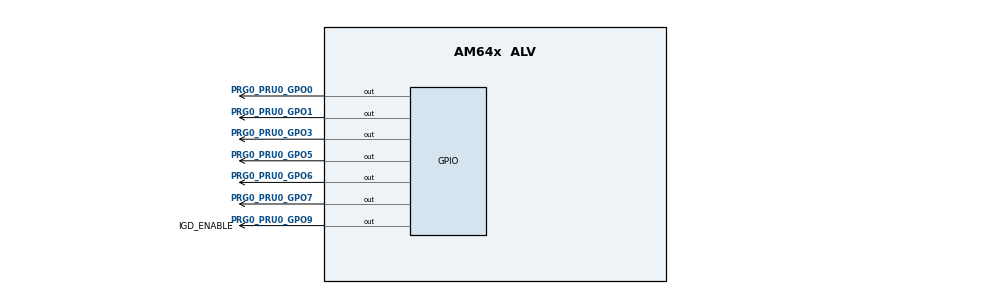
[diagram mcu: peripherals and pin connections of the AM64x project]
/**
 * @cliArgs --device "AM64x" --part "Default" --package "ALV" --context "r5fss0-0" --product "MCU_PLUS_SDK_AM64x@09.02.01"
 * @versions {"tool":"1.21.0+3721"}
 */

/**
 * Import the modules used in this configuration.
 */
const epwm       = scripting.addModule("/drivers/epwm/epwm", {}, false);
const epwm1      = epwm.addInstance();
const epwm2      = epwm.addInstance();
const epwm3      = epwm.addInstance();
const epwm4      = epwm.addInstance();
const gpio       = scripting.addModule("/drivers/gpio/gpio", {}, false);
const gpio1      = gpio.addInstance();
const gpio2      = gpio.addInstance();
const gpio3      = gpio.addInstance();
const gpio4      = gpio.addInstance();
const gpio5      = gpio.addInstance();
const gpio6      = gpio.addInstance();
const gpio7      = gpio.addInstance();
const i2c        = scripting.addModule("/drivers/i2c/i2c", {}, false);
const i2c1       = i2c.addInstance();
const mcspi      = scripting.addModule("/drivers/mcspi/mcspi", {}, false);
const mcspi1     = mcspi.addInstance();
const pruicss    = scripting.addModule("/drivers/pruicss/pruicss", {}, false);
const pruicss1   = pruicss.addInstance();
const udma       = scripting.addModule("/drivers/udma/udma", {}, false);
const udma1      = udma.addInstance();
const clock      = scripting.addModule("/kernel/dpl/clock");
const debug_log  = scripting.addModule("/kernel/dpl/debug_log");
const mpu_armv7  = scripting.addModule("/kernel/dpl/mpu_armv7", {}, false);
const mpu_armv71 = mpu_armv7.addInstance();
const mpu_armv72 = mpu_armv7.addInstance();
const mpu_armv73 = mpu_armv7.addInstance();
const mpu_armv74 = mpu_armv7.addInstance();
const mpu_armv75 = mpu_armv7.addInstance();
const mpu_armv76 = mpu_armv7.addInstance();
const pru_ipc    = scripting.addModule("/pru_io/pru_ipc/pru_ipc", {}, false);
const pru_ipc1   = pru_ipc.addInstance();

/**
 * Write custom configuration values to the imported modules.
 */
epwm1.$name            = "CONFIG_EPWM1";
epwm1.EPWM.$assign     = "EHRPWM4";
epwm1.EPWM.SYNCO.$used = false;
epwm1.EPWM.SYNCI.$used = false;

epwm2.$name            = "CONFIG_EPWM2";
epwm2.EPWM.$assign     = "EHRPWM5";
epwm2.EPWM.SYNCO.$used = false;
epwm2.EPWM.SYNCI.$used = false;

epwm3.$name            = "CONFIG_EPWM3";
epwm3.EPWM.$assign     = "EHRPWM6";
epwm3.EPWM.A.$assign   = "SPI1_CS0";
epwm3.EPWM.B.$assign   = "SPI1_D1";
epwm3.EPWM.SYNCO.$used = false;
epwm3.EPWM.SYNCI.$used = false;

epwm4.$name            = "CONFIG_EPWM0";
epwm4.EPWM.$assign     = "EHRPWM3";
epwm4.EPWM.A.$used     = false;
epwm4.EPWM.B.$used     = false;
epwm4.EPWM.SYNCO.$used = false;
epwm4.EPWM.SYNCI.$used = false;

gpio1.$name                = "CONFIG_GPIO0";
gpio1.pinDir               = "OUTPUT";
gpio1.trigType             = "BOTH_EDGE";
gpio1.GPIO.gpioPin.rx      = false;
gpio1.GPIO.gpioPin.$assign = "PRG0_PRU0_GPO0";

gpio2.$name                = "CONFIG_GPIO1";
gpio2.trigType             = "BOTH_EDGE";
gpio2.pinDir               = "OUTPUT";
gpio2.GPIO.gpioPin.rx      = false;
gpio2.GPIO.gpioPin.$assign = "PRG0_PRU0_GPO1";

gpio3.$name                = "CONFIG_GPIO2";
gpio3.trigType             = "BOTH_EDGE";
gpio3.pinDir               = "OUTPUT";
gpio3.GPIO.gpioPin.rx      = false;
gpio3.GPIO.gpioPin.$assign = "PRG0_PRU0_GPO3";

gpio4.$name                = "CONFIG_GPIO3";
gpio4.pinDir               = "OUTPUT";
gpio4.trigType             = "BOTH_EDGE";
gpio4.GPIO.gpioPin.rx      = false;
gpio4.GPIO.gpioPin.$assign = "PRG0_PRU0_GPO5";

gpio5.$name                = "CONFIG_GPIO4";
gpio5.pinDir               = "OUTPUT";
gpio5.trigType             = "BOTH_EDGE";
gpio5.GPIO.gpioPin.rx      = false;
gpio5.GPIO.gpioPin.$assign = "PRG0_PRU0_GPO6";

gpio6.$name                = "CONFIG_GPIO5";
gpio6.pinDir               = "OUTPUT";
gpio6.trigType             = "BOTH_EDGE";
gpio6.GPIO.$assign         = "GPIO1";
gpio6.GPIO.gpioPin.rx      = false;
gpio6.GPIO.gpioPin.$assign = "PRG0_PRU0_GPO7";

gpio7.pinDir               = "OUTPUT";
gpio7.$name                = "IGD_ENABLE";
gpio7.GPIO.gpioPin.rx      = false;
gpio7.GPIO.gpioPin.$assign = "PRG0_PRU0_GPO9";

i2c1.$name               = "CONFIG_I2C0";
i2c1.transferMode        = "CALLBACK";
i2c1.transferCallbackFxn = "i2cCallback";
i2c1.ownTargetAddr1      = 0x70;
i2c1.I2C.$assign         = "I2C1";
i2c1.I2C_child.$name     = "drivers_i2c_v0_i2c_v0_template0";

mcspi1.$name                       = "CONFIG_MCSPI0";
mcspi1.intrEnable                  = "DMA";
mcspi1.errorCallbackFxn            = "Ads8688_ErrorCb";
mcspi1.txFifoTrigLevel             = 2;
mcspi1.rxFifoTrigLevel             = 2;
mcspi1.SPI.$assign                 = "SPI0";
mcspi1.SPI.CLK.rx                  = false;
mcspi1.SPI.D0.rx                   = false;
mcspi1.mcspiChannel[0].$name       = "CONFIG_MCSPI_CH0";
mcspi1.mcspiChannel[0].frameFormat = "POL0_PHA1";
mcspi1.mcspiChannel[0].bitRate     = 10000000;
mcspi1.mcspiChannel[0].CSn.rx      = false;
mcspi1.child.$name                 = "drivers_mcspi_v0_mcspi_v0_template0";

pruicss1.$name                                                                      = "CONFIG_PRU_ICSS0";
pruicss1.iepSyncMode                                                                = true;
pruicss1.AdditionalICSSSettings[0].$name                                            = "CONFIG_PRU_ICSS_IO0";
pruicss1.AdditionalICSSSettings[0].PruGPIO.create(1);
pruicss1.AdditionalICSSSettings[0].PruGPIO[0].$name                                 = "CONFIG_PRU_ICSS_GPIO0";
pruicss1.AdditionalICSSSettings[0].PruGPIO[0].PRU_ICSSG0_PRU.$assign                = "PRU_ICSSG0_PRU0";
pruicss1.AdditionalICSSSettings[0].PruGPIO[0].PRU_ICSSG0_PRU.GPI0.rx                = false;
pruicss1.AdditionalICSSSettings[0].PruGPIO[0].PRU_ICSSG0_PRU.GPI1.rx                = false;
pruicss1.AdditionalICSSSettings[0].PruGPIO[0].PRU_ICSSG0_PRU.GPI10.rx               = false;
pruicss1.AdditionalICSSSettings[0].PruGPIO[0].PRU_ICSSG0_PRU.GPI11.rx               = false;
pruicss1.AdditionalICSSSettings[0].PruGPIO[0].PRU_ICSSG0_PRU.GPI12.rx               = false;
pruicss1.AdditionalICSSSettings[0].PruGPIO[0].PRU_ICSSG0_PRU.GPI13.rx               = false;
pruicss1.AdditionalICSSSettings[0].PruGPIO[0].PRU_ICSSG0_PRU.GPI14.rx               = false;
pruicss1.AdditionalICSSSettings[0].PruGPIO[0].PRU_ICSSG0_PRU.GPI15.rx               = false;
pruicss1.AdditionalICSSSettings[0].PruGPIO[0].PRU_ICSSG0_PRU.GPI16.rx               = false;
pruicss1.AdditionalICSSSettings[0].PruGPIO[0].PRU_ICSSG0_PRU.GPI17.rx               = false;
pruicss1.AdditionalICSSSettings[0].PruGPIO[0].PRU_ICSSG0_PRU.GPI18.rx               = false;
pruicss1.AdditionalICSSSettings[0].PruGPIO[0].PRU_ICSSG0_PRU.GPI19.rx               = false;
pruicss1.AdditionalICSSSettings[0].PruGPIO[0].PRU_ICSSG0_PRU.GPI2.rx                = false;
pruicss1.AdditionalICSSSettings[0].PruGPIO[0].PRU_ICSSG0_PRU.GPI3.rx                = false;
pruicss1.AdditionalICSSSettings[0].PruGPIO[0].PRU_ICSSG0_PRU.GPI4.rx                = false;
pruicss1.AdditionalICSSSettings[0].PruGPIO[0].PRU_ICSSG0_PRU.GPI5.rx                = false;
pruicss1.AdditionalICSSSettings[0].PruGPIO[0].PRU_ICSSG0_PRU.GPI6.rx                = false;
pruicss1.AdditionalICSSSettings[0].PruGPIO[0].PRU_ICSSG0_PRU.GPI7.rx                = false;
pruicss1.AdditionalICSSSettings[0].PruGPIO[0].PRU_ICSSG0_PRU.GPI8.rx                = false;
pruicss1.AdditionalICSSSettings[0].PruGPIO[0].PRU_ICSSG0_PRU.GPI9.rx                = false;
pruicss1.AdditionalICSSSettings[0].PruIepIO.create(1);
pruicss1.AdditionalICSSSettings[0].PruIepIO[0].$name                                = "CONFIG_PRU_ICSS_IEP_IO0";
pruicss1.AdditionalICSSSettings[0].PruIepIO[0].PRU_ICSSG0_IEP.$assign               = "PRU_ICSSG0_IEP0";
pruicss1.AdditionalICSSSettings[0].PruIepIO[0].PRU_ICSSG0_IEP.EDC_LATCH_IN0.$assign = "PRG0_PRU0_GPO18";
pruicss1.AdditionalICSSSettings[0].PruIepIO[0].PRU_ICSSG0_IEP.EDC_LATCH_IN1.$assign = "PRG0_PRU0_GPO7";
pruicss1.AdditionalICSSSettings[0].PruIepIO[0].PRU_ICSSG0_IEP.EDC_SYNC_OUT0.$assign = "PRG0_PRU0_GPO19";
pruicss1.AdditionalICSSSettings[0].PruIepIO[0].PRU_ICSSG0_IEP.EDC_SYNC_OUT1.$assign = "PRG0_PRU0_GPO17";
pruicss1.AdditionalICSSSettings[0].PruEcapIO.create(1);
pruicss1.AdditionalICSSSettings[0].PruEcapIO[0].$name                               = "CONFIG_PRU_ICSS_ECAP_IO0";
pruicss1.AdditionalICSSSettings[0].PruEcapIO[0].PRU_ICSSG0_ECAP.$assign             = "PRU_ICSSG0_ECAP0";
pruicss1.AdditionalICSSSettings[0].PruEcapIO[0].PRU_ICSSG0_ECAP.IN_APWM_OUT.pu_pd   = "pd";
pruicss1.AdditionalICSSSettings[0].PruEcapIO[0].PRU_ICSSG0_ECAP.IN_APWM_OUT.rx      = true;
pruicss1.AdditionalICSSSettings[0].PruEcapIO[0].PRU_ICSSG0_ECAP.IN_APWM_OUT.$assign = "PRG0_PRU1_GPO15";
pruicss1.AdditionalICSSSettings[0].PruEcapIO[0].PRU_ICSSG0_ECAP.IN_APWM_OUT.$used   = true;
pruicss1.intcMapping.create(1);
pruicss1.intcMapping[0].$name                                                       = "CONFIG_ICSS0_INTC_MAPPING2";
pruicss1.intcMapping[0].event                                                       = "17";
pruicss1.intcMapping[0].channel                                                     = "1";

udma1.$name       = "CONFIG_UDMA0";
mcspi1.udmaDriver = udma1;

mpu_armv71.$name             = "CONFIG_MPU_REGION0";
mpu_armv71.size              = 31;
mpu_armv71.attributes        = "Device";
mpu_armv71.accessPermissions = "Supervisor RD+WR, User RD";
mpu_armv71.allowExecute      = false;

mpu_armv72.$name             = "CONFIG_MPU_REGION1";
mpu_armv72.size              = 15;
mpu_armv72.accessPermissions = "Supervisor RD+WR, User RD";

mpu_armv73.$name             = "CONFIG_MPU_REGION2";
mpu_armv73.baseAddr          = 0x41010000;
mpu_armv73.size              = 15;
mpu_armv73.accessPermissions = "Supervisor RD+WR, User RD";

mpu_armv74.$name             = "CONFIG_MPU_REGION3";
mpu_armv74.baseAddr          = 0x70000000;
mpu_armv74.size              = 21;
mpu_armv74.accessPermissions = "Supervisor RD+WR, User RD";

mpu_armv75.$name             = "CONFIG_MPU_REGION4";
mpu_armv75.baseAddr          = 0x60000000;
mpu_armv75.size              = 28;
mpu_armv75.accessPermissions = "Supervisor RD, User RD";

mpu_armv76.$name    = "CONFIG_MPU_REGION5";
mpu_armv76.baseAddr = 0x80000000;
mpu_armv76.size     = 31;

pru_ipc1.$name                 = "CONFIG_PRU_IPC0";
pru_ipc1.rxIntcMapping.$name   = "CONFIG_ICSS0_INTC_MAPPING0";
pru_ipc1.rxIntcMapping.channel = "0";
pru_ipc1.rxIntcMapping.host    = "2";

/**
 * Pinmux solution for unlocked pins/peripherals. This ensures that minor changes to the automatic solver in a future
 * version of the tool will not impact the pinmux you originally saw.  These lines can be completely deleted in order to
 * re-solve from scratch.
 */
epwm1.EPWM.A.$suggestSolution               = "GPMC0_OEn_REn";
epwm1.EPWM.B.$suggestSolution               = "GPMC0_WEn";
epwm2.EPWM.A.$suggestSolution               = "GPMC0_BE1n";
epwm2.EPWM.B.$suggestSolution               = "GPMC0_WAIT0";
gpio1.GPIO.$suggestSolution                 = "GPIO1";
gpio2.GPIO.$suggestSolution                 = "GPIO1";
gpio3.GPIO.$suggestSolution                 = "GPIO1";
gpio4.GPIO.$suggestSolution                 = "GPIO1";
gpio5.GPIO.$suggestSolution                 = "GPIO1";
gpio7.GPIO.$suggestSolution                 = "GPIO1";
i2c1.I2C.SCL.$suggestSolution               = "I2C1_SCL";
i2c1.I2C.SDA.$suggestSolution               = "I2C1_SDA";
mcspi1.SPI.CLK.$suggestSolution             = "SPI0_CLK";
mcspi1.SPI.D0.$suggestSolution              = "SPI0_D0";
mcspi1.SPI.D1.$suggestSolution              = "SPI0_D1";
mcspi1.mcspiChannel[0].CSn.$suggestSolution = "SPI0_CS0";
